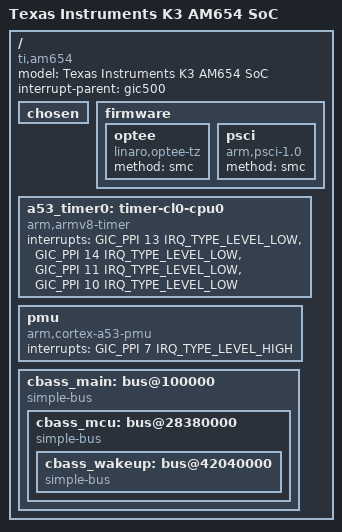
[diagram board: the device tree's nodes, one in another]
#include <dt-bindings/gpio/gpio.h>
#include <dt-bindings/interrupt-controller/irq.h>
#include <dt-bindings/interrupt-controller/arm-gic.h>
#include <dt-bindings/soc/ti,sci_pm_domain.h>
#include "k3-pinctrl.h"
/ {
	model = "Texas Instruments K3 AM654 SoC";
	compatible = "ti,am654";
	interrupt-parent = <&gic500>;
	#address-cells = <2>;
	#size-cells = <2>;
	chosen { };
	firmware {
		optee {
			compatible = "linaro,optee-tz";
			method = "smc";
		};
		psci: psci {
			compatible = "arm,psci-1.0";
			method = "smc";
		};
	};
	a53_timer0: timer-cl0-cpu0 {
		compatible = "arm,armv8-timer";
		interrupts = <GIC_PPI 13 IRQ_TYPE_LEVEL_LOW>,  
			     <GIC_PPI 14 IRQ_TYPE_LEVEL_LOW>,  
			     <GIC_PPI 11 IRQ_TYPE_LEVEL_LOW>,  
			     <GIC_PPI 10 IRQ_TYPE_LEVEL_LOW>;  
	};
	pmu: pmu {
		compatible = "arm,cortex-a53-pmu";
		interrupts = <GIC_PPI 7 IRQ_TYPE_LEVEL_HIGH>;
	};
	cbass_main: bus@100000 {
		compatible = "simple-bus";
		#address-cells = <2>;
		#size-cells = <2>;
		ranges = <0x00 0x00100000 0x00 0x00100000 0x00 0x00020000>,  
			 <0x00 0x00600000 0x00 0x00600000 0x00 0x00001100>,  
			 <0x00 0x00900000 0x00 0x00900000 0x00 0x00012000>,  
			 <0x00 0x01000000 0x00 0x01000000 0x00 0x0af02400>,  
			 <0x00 0x30800000 0x00 0x30800000 0x00 0x0bc00000>,  
			 <0x00 0x70000000 0x00 0x70000000 0x00 0x00200000>,  
			 <0x00 0x10000000 0x00 0x10000000 0x00 0x10000000>,  
			 <0x00 0x28380000 0x00 0x28380000 0x00 0x03880000>,
			 <0x00 0x40200000 0x00 0x40200000 0x00 0x00900100>,
			 <0x00 0x40f00000 0x00 0x40f00000 0x00 0x00020000>,  
			 <0x00 0x41000000 0x00 0x41000000 0x00 0x00020000>,
			 <0x00 0x41400000 0x00 0x41400000 0x00 0x00020000>,
			 <0x00 0x41c00000 0x00 0x41c00000 0x00 0x00080000>,
			 <0x00 0x42040000 0x00 0x42040000 0x00 0x03ac2400>,
			 <0x00 0x45100000 0x00 0x45100000 0x00 0x00c24000>,
			 <0x00 0x46000000 0x00 0x46000000 0x00 0x00200000>,
			 <0x00 0x47000000 0x00 0x47000000 0x00 0x00068400>,
			 <0x00 0x50000000 0x00 0x50000000 0x00 0x8000000>,
			 <0x00 0x6f000000 0x00 0x6f000000 0x00 0x00310000>,  
			 <0x00 0x70000000 0x00 0x70000000 0x00 0x200000>,
			 <0x05 0x00000000 0x05 0x00000000 0x01 0x0000000>,
			 <0x07 0x00000000 0x07 0x00000000 0x01 0x0000000>;
		cbass_mcu: bus@28380000 {
			compatible = "simple-bus";
			#address-cells = <2>;
			#size-cells = <2>;
			ranges = <0x00 0x28380000 0x00 0x28380000 0x00 0x03880000>,  
				 <0x00 0x40200000 0x00 0x40200000 0x00 0x00900100>,  
				 <0x00 0x40f00000 0x00 0x40f00000 0x00 0x00020000>,  
				 <0x00 0x41000000 0x00 0x41000000 0x00 0x00020000>,  
				 <0x00 0x41400000 0x00 0x41400000 0x00 0x00020000>,  
				 <0x00 0x41c00000 0x00 0x41c00000 0x00 0x00080000>,  
				 <0x00 0x42040000 0x00 0x42040000 0x00 0x03ac2400>,  
				 <0x00 0x45100000 0x00 0x45100000 0x00 0x00c24000>,  
				 <0x00 0x46000000 0x00 0x46000000 0x00 0x00200000>,  
				 <0x00 0x47000000 0x00 0x47000000 0x00 0x00068400>,  
				 <0x00 0x50000000 0x00 0x50000000 0x00 0x8000000>,  
				 <0x05 0x00000000 0x05 0x00000000 0x01 0x0000000>,  
				 <0x07 0x00000000 0x07 0x00000000 0x01 0x0000000>;  
			cbass_wakeup: bus@42040000 {
				compatible = "simple-bus";
				#address-cells = <1>;
				#size-cells = <1>;
				ranges = <0x42040000 0x00 0x42040000 0x03ac2400>;
			};
		};
	};
};
#include "k3-am65-main.dtsi"
#include "k3-am65-mcu.dtsi"
#include "k3-am65-wakeup.dtsi"
